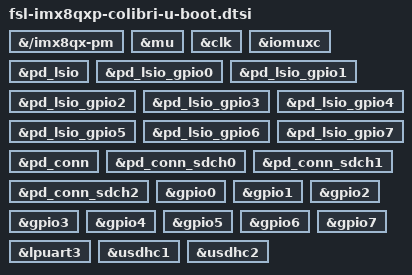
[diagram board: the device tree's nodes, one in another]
// SPDX-License-Identifier: GPL-2.0+ OR X11
/*
 * Copyright 2019 Toradex AG
 */

&{/imx8qx-pm} {

	u-boot,dm-spl;
};

&mu {
	u-boot,dm-spl;
};

&clk {
	u-boot,dm-spl;
};

&iomuxc {
	u-boot,dm-spl;
};

&pd_lsio {
	u-boot,dm-spl;
};

&pd_lsio_gpio0 {
	u-boot,dm-spl;
};

&pd_lsio_gpio1 {
	u-boot,dm-spl;
};

&pd_lsio_gpio2 {
	u-boot,dm-spl;
};

&pd_lsio_gpio3 {
	u-boot,dm-spl;
};

&pd_lsio_gpio4 {
	u-boot,dm-spl;
};

&pd_lsio_gpio5 {
	u-boot,dm-spl;
};

&pd_lsio_gpio6 {
	u-boot,dm-spl;
};

&pd_lsio_gpio7 {
	u-boot,dm-spl;
};

&pd_conn {
	u-boot,dm-spl;
};

&pd_conn_sdch0 {
	u-boot,dm-spl;
};

&pd_conn_sdch1 {
	u-boot,dm-spl;
};

&pd_conn_sdch2 {
	u-boot,dm-spl;
};

&gpio0 {
	u-boot,dm-spl;
};

&gpio1 {
	u-boot,dm-spl;
};

&gpio2 {
	u-boot,dm-spl;
};

&gpio3 {
	u-boot,dm-spl;
};

&gpio4 {
	u-boot,dm-spl;
};

&gpio5 {
	u-boot,dm-spl;
};

&gpio6 {
	u-boot,dm-spl;
};

&gpio7 {
	u-boot,dm-spl;
};

&lpuart3 {
	u-boot,dm-spl;
};

&usdhc1 {
	u-boot,dm-spl;
};

&usdhc2 {
	u-boot,dm-spl;
};
